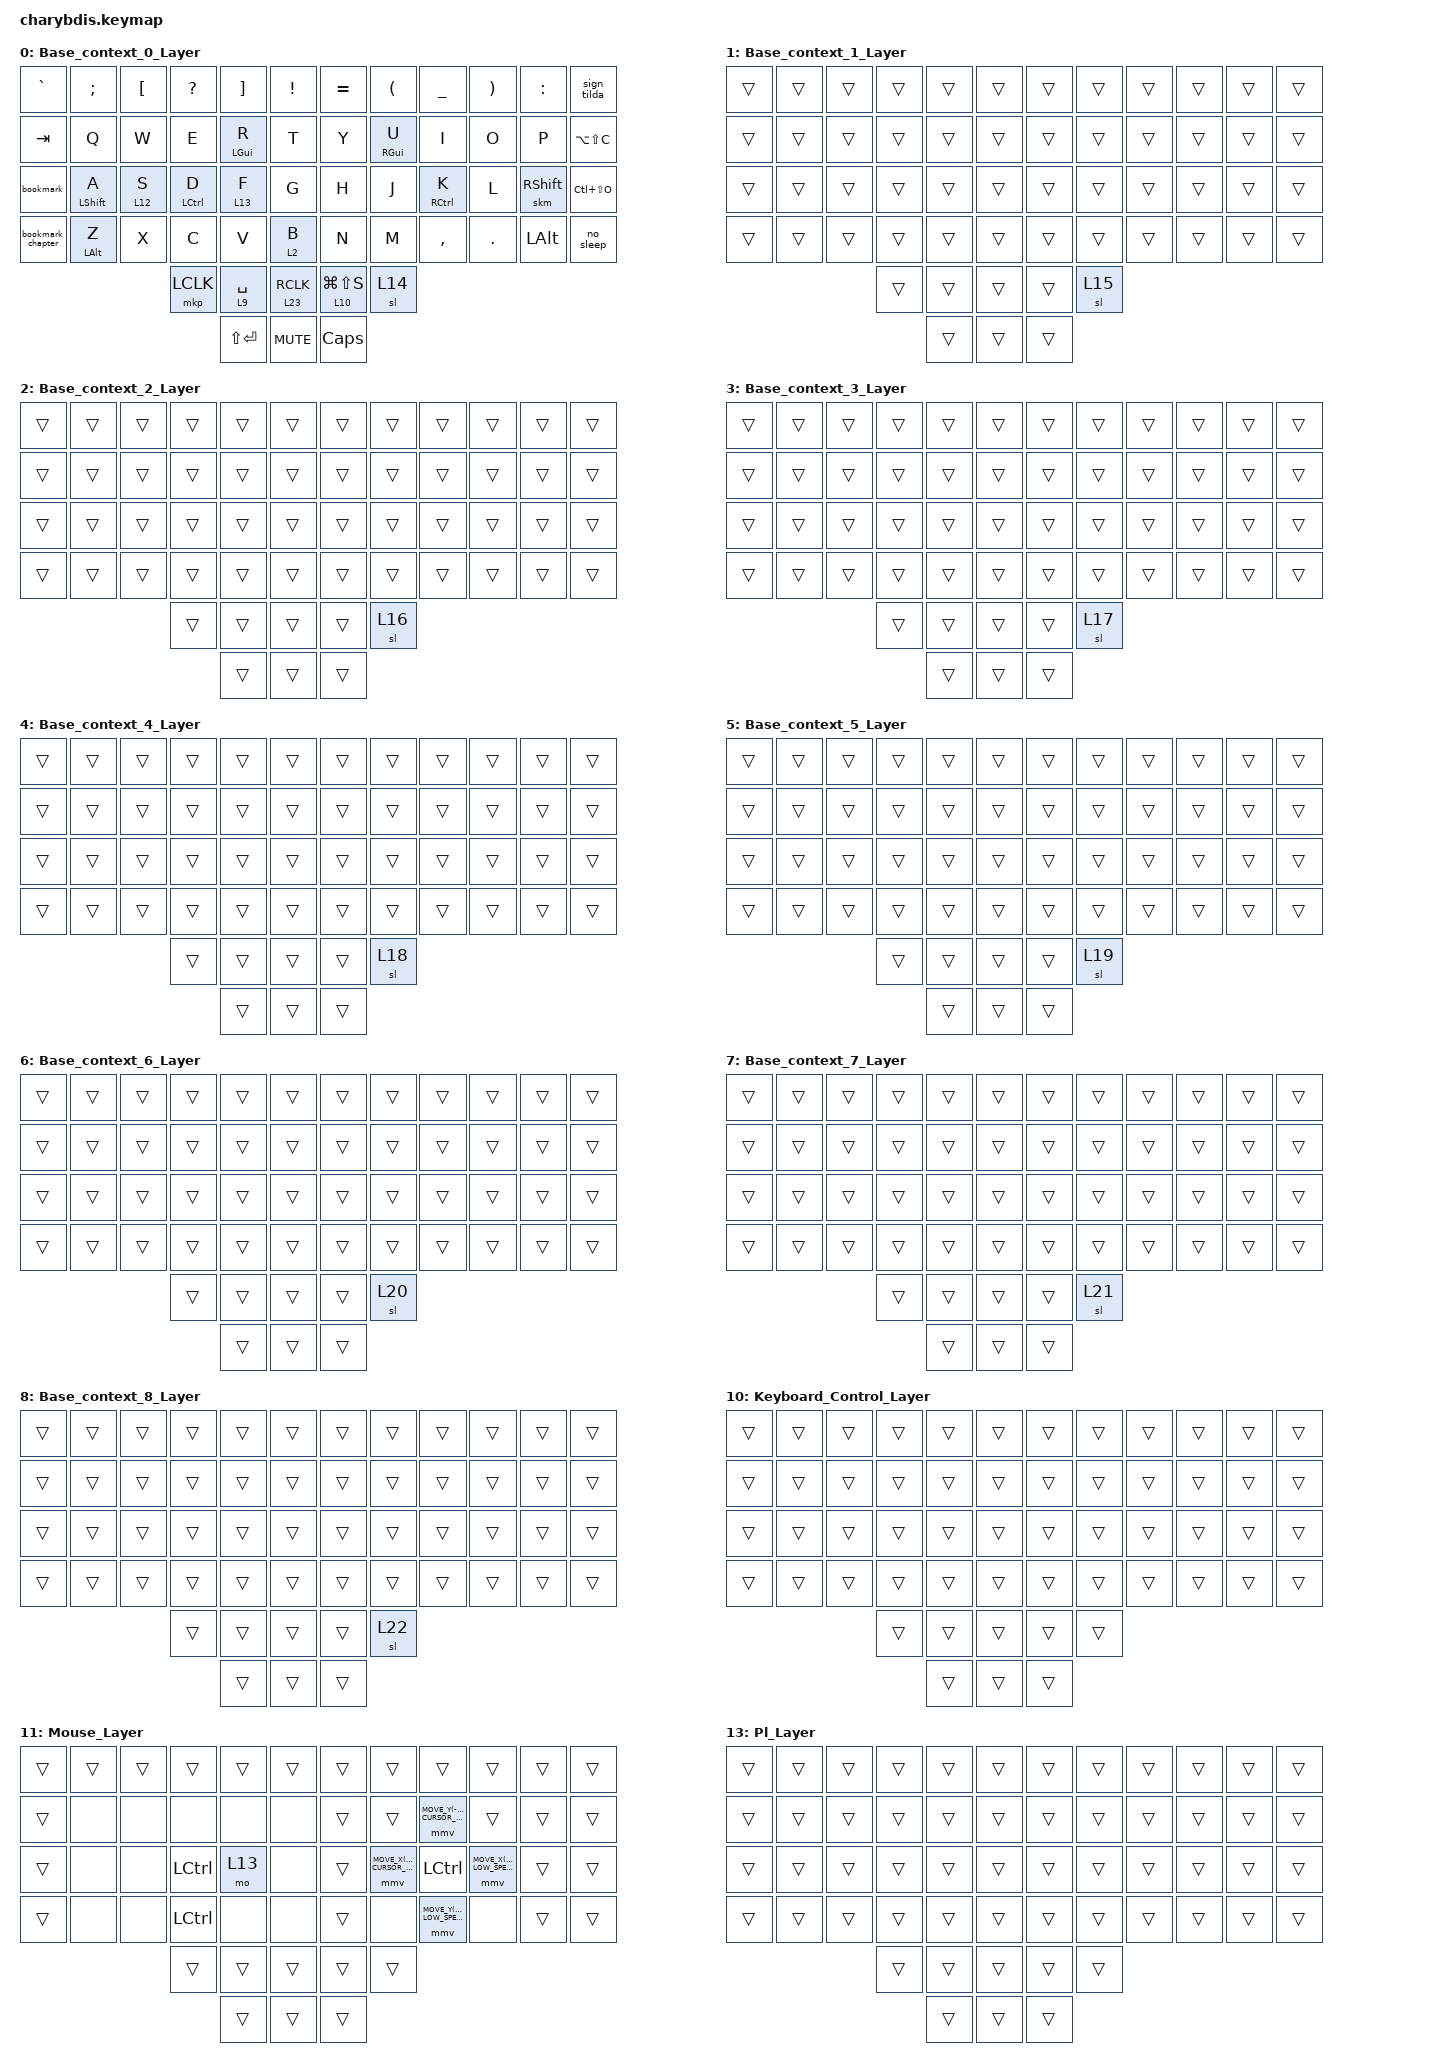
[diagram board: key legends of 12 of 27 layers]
#include <behaviors.dtsi>
#include <dt-bindings/zmk/keys.h>
#include <dt-bindings/zmk/pointing.h>

#define SIGN_COMBOS_LAYERS 0 1 2 3 4 5 6 7 8 9
#define SIGN_COMBOS_DELAY 40
#define SELECT_COMBOS_LAYERS 9
#define SELECT_COMBOS_DELAY 50
#define KEY_CURSOR_HIGH_SPEED 1200
#define KEY_CURSOR_LOW_SPEED  800

&lt {
    tapping-term-ms = <200>;
    flavor = "balanced";
    quick-tap-ms = <150>;
};

/ {
    behaviors {
        mmt: mmt {
            compatible = "zmk,behavior-hold-tap";
            #binding-cells = <2>;
            flavor = "balanced";
            tapping-term-ms = <200>;
            quick-tap-ms = <200>;
            global-quick-tap;
            bindings = <&kp>, <&kp>;
        };

        skl: skl {
            compatible = "zmk,behavior-sticky-key";
            label = "skl";
            #binding-cells = <1>;
            bindings = <&mo>;
            release-after-ms = <1000>;
            quick-release;
            ignore-modifiers;
        };

        skm: sticky_modif {
            compatible = "zmk,behavior-sticky-key";
            #binding-cells = <1>;
            bindings = <&kp>;
            release-after-ms = <1000>;
            quick-release;
        };

        // Define your custom delayed layer-tap behavior

        lt_delay: layer_tap_delay {
            compatible = "zmk,behavior-hold-tap";
            #binding-cells = <2>;
            flavor = "balanced";         // Enforces the time lag
            tapping-term-ms = <300>;           // Your time lag duration (e.g., 300ms)
            bindings = <&mo>, <&kp>;

            // Hold triggers momentary layer, tap triggers keypress
        };

        my_lt_rclk: my_lt_rclk {
            compatible = "zmk,behavior-hold-tap";
            #binding-cells = <2>;
            flavor = "tap-preferred"; // or "balanced" / "hold-preferred"
            tapping-term-ms = <200>;
            quick-tap-ms = <0>;
            bindings = <&mo>, <&mkp>;
        };
    };
};

/ {
    combos {
        compatible = "zmk,combos";

        sign_minus {
            timeout-ms = <SIGN_COMBOS_DELAY>;
            key-positions = <32 31>; // Triggers when positions 13 and 14 are pressed together
            bindings = <&kp MINUS>;    // Outputs the Escape key
            layers = <SIGN_COMBOS_LAYERS>;
        };

        sign_plus {
            timeout-ms = <SIGN_COMBOS_DELAY>;
            bindings = <&kp RS(PLUS)>;
            key-positions = <33 32>;
            layers = <SIGN_COMBOS_LAYERS>;
        };

        sign_asterix {
            timeout-ms = <SIGN_COMBOS_DELAY>;
            bindings = <&kp ASTERISK>;
            key-positions = <45 44>;
            layers = <SIGN_COMBOS_LAYERS>;
        };

        sign_divide {
            timeout-ms = <SIGN_COMBOS_DELAY>;
            bindings = <&kp SLASH>;
            key-positions = <44 43>;
            layers = <SIGN_COMBOS_LAYERS>;
        };

        sign_dollar {
            timeout-ms = <SIGN_COMBOS_DELAY>;
            bindings = <&kp DOLLAR>;
            key-positions = <20 19>;
            layers = <SIGN_COMBOS_LAYERS>;
        };

        sign_percent {
            timeout-ms = <SIGN_COMBOS_DELAY>;
            bindings = <&kp PERCENT>;
            key-positions = <21 20>;
            layers = <SIGN_COMBOS_LAYERS>;
        };

        sign_backslash {
            timeout-ms = <SIGN_COMBOS_DELAY>;
            bindings = <&kp BACKSLASH>;
            key-positions = <43 42>;
            layers = <SIGN_COMBOS_LAYERS>;
        };

        sign_at {
            timeout-ms = <SIGN_COMBOS_DELAY>;
            bindings = <&kp AT>;
            key-positions = <19 18>;
            layers = <SIGN_COMBOS_LAYERS>;
        };

        sign_caret {
            timeout-ms = <SIGN_COMBOS_DELAY>;
            bindings = <&kp CARET>;
            key-positions = <31 30>;
            layers = <SIGN_COMBOS_LAYERS>;
        };

        sign_double_quote {
            timeout-ms = <SIGN_COMBOS_DELAY>;
            bindings = <&kp DOUBLE_QUOTES>;
            key-positions = <21 19>;
            layers = <SIGN_COMBOS_LAYERS>;
        };

        sign_single_quote {
            bindings = <&kp SINGLE_QUOTE>;
            key-positions = <33 31>;
            layers = <SIGN_COMBOS_LAYERS>;
        };

        sign_pipe {
            timeout-ms = <SIGN_COMBOS_DELAY>;
            bindings = <&kp PIPE>;
            key-positions = <45 43>;
            layers = <SIGN_COMBOS_LAYERS>;
        };

        sign_hash {
            timeout-ms = <SIGN_COMBOS_DELAY>;
            bindings = <&kp HASH>;
            key-positions = <41 40>;
            layers = <SIGN_COMBOS_LAYERS>;
        };

        sign_amper {
            timeout-ms = <SIGN_COMBOS_DELAY>;
            bindings = <&kp AMPERSAND>;
            key-positions = <46 45>;
            layers = <SIGN_COMBOS_LAYERS>;
        };

        sign_l_brace {
            timeout-ms = <SIGN_COMBOS_DELAY>;
            bindings = <&kp LEFT_BRACE>;
            key-positions = <22 21>;
            layers = <SIGN_COMBOS_LAYERS>;
        };

        sign_r_brace {
            timeout-ms = <SIGN_COMBOS_DELAY>;
            bindings = <&kp RIGHT_BRACE>;
            key-positions = <34 33>;
            layers = <SIGN_COMBOS_LAYERS>;
        };

        sign_less {
            timeout-ms = <SIGN_COMBOS_DELAY>;
            bindings = <&kp LESS_THAN>;
            key-positions = <17 16>;
            layers = <SIGN_COMBOS_LAYERS>;
        };

        sign_greater {
            timeout-ms = <SIGN_COMBOS_DELAY>;
            bindings = <&kp GREATER_THAN>;
            key-positions = <29 28>;
            layers = <SIGN_COMBOS_LAYERS>;
        };

        mouse_scroll_down {
            timeout-ms = <SIGN_COMBOS_DELAY>;
            bindings = <&msc SCRL_DOWN>;
            key-positions = <40 38>;
            layers = <0 1 2 3 4 5 6 7 8 11>;
        };

        mouse_scroll_up {
            timeout-ms = <SIGN_COMBOS_DELAY>;
            bindings = <&msc SCRL_UP>;
            key-positions = <28 26>;
            layers = <0 1 2 3 4 5 6 7 8 11>;
        };

        mouse_left_click {
            timeout-ms = <SIGN_COMBOS_DELAY>;
            bindings = <&mkp MB1>;
            key-positions = <28 27>;
            layers = <0 1 2 3 4 5 6 7 8 11 12>;
        };

        mouse_right_click {
            timeout-ms = <SIGN_COMBOS_DELAY>;
            bindings = <&mkp MB2>;
            key-positions = <27 26>;
            layers = <0 1 2 3 4 5 6 7 8 11 12>;
        };

        mouse_back_click {
            timeout-ms = <SIGN_COMBOS_DELAY>;
            bindings = <&mkp MB4>;
            key-positions = <26 25>;
            layers = <0 1 2 3 4 5 6 7 8 11>;
        };

        mouse_forward_click {
            timeout-ms = <SIGN_COMBOS_DELAY>;
            bindings = <&mkp MB5>;
            key-positions = <38 37>;
            layers = <0 1 2 3 4 5 6 7 8 11>;
        };

        select_all {
            timeout-ms = <SELECT_COMBOS_DELAY>;
            bindings = <&kp LC(A)>;
            key-positions = <16 14>;
            layers = <SELECT_COMBOS_LAYERS>;
        };

        select_all_before {
            timeout-ms = <SELECT_COMBOS_DELAY>;
            bindings = <&kt RC(RS(HOME))>;
            key-positions = <15 14>;
            layers = <SELECT_COMBOS_LAYERS>;
        };

        select_all_after {
            timeout-ms = <SELECT_COMBOS_DELAY>;
            bindings = <&kp RC(RS(END))>;
            key-positions = <16 15>;
            layers = <SELECT_COMBOS_LAYERS>;
        };

        select_line_before {
            timeout-ms = <SELECT_COMBOS_DELAY>;
            bindings = <&kp RS(HOME)>;
            key-positions = <27 26>;
            layers = <SELECT_COMBOS_LAYERS>;
        };

        select_line_after {
            timeout-ms = <SELECT_COMBOS_DELAY>;
            bindings = <&kp RS(END)>;
            key-positions = <28 27>;
            layers = <SELECT_COMBOS_LAYERS>;
        };

        select_line_whole {
            timeout-ms = <SELECT_COMBOS_DELAY>;
            bindings = <&select_line>;
            key-positions = <28 26>;
            layers = <SELECT_COMBOS_LAYERS>;
        };

        select_world_whole {
            timeout-ms = <SELECT_COMBOS_DELAY>;
            bindings = <&select_word>;
            key-positions = <40 38>;
            layers = <SELECT_COMBOS_LAYERS>;
        };

        quick_layer_sl_1 {
            timeout-ms = <40>;
            bindings = <&sl 24>;
            key-positions = <40 39>;
            layers = <0 1 2 3 4 5 6 7 8>;
        };

        quick_layer_sl_2 {
            timeout-ms = <40>;
            bindings = <&sl 25>;
            key-positions = <39 38>;
            layers = <0 1 2 3 4 5 6 7 8>;
        };
    };
};

/ {
    macros {
        un: un {
            compatible = "zmk,behavior-macro";
            #binding-cells = <0>;
            bindings = <&kp U &kp N &kp N9 &kp N9 &kp L &kp T>;
            label = "UN";
        };

        ad: ad {
            compatible = "zmk,behavior-macro";
            #binding-cells = <0>;
            bindings = <&kp A &kp D &kp BSLH>;
            label = "AD";
        };

        email_w: email_w {
            compatible = "zmk,behavior-macro";
            #binding-cells = <0>;
            bindings = <&kp L &kp U &kp K &kp A &kp S &kp Z &kp DOT &kp M &kp U &kp S &kp Z &kp Y &kp N &kp S &kp K &kp I &kp AT &kp I &kp N &kp G &kp DOT &kp P &kp L>;
            label = "EMAIL_W";
        };

        passport: passport {
            compatible = "zmk,behavior-macro";
            #binding-cells = <0>;
            bindings = <&kp LS(E) &kp LS(R) &kp N6 &kp N7 &kp N8 &kp N4 &kp N8 &kp N1 &kp N9>;
            label = "PASSPORT";
        };

        id: id {
            compatible = "zmk,behavior-macro";
            #binding-cells = <0>;
            bindings = <&kp LS(D) &kp LS(E) &kp LS(R) &kp N6 &kp N1 &kp N1 &kp N2 &kp N4 &kp N2>;
            label = "ID";
        };

        email_h: email_h {
            compatible = "zmk,behavior-macro";
            #binding-cells = <0>;
            bindings = <&kp L &kp U &kp K &kp A &kp S &kp Z &kp M &kp U &kp S &kp Z &kp Y &kp N &kp S &kp K &kp I &kp N0 &kp AT &kp G &kp M &kp A &kp I &kp L &kp DOT &kp C &kp O &kp M>;
            label = "EMAIL_H";
        };

        email_h_spam: email_h_spam {
            compatible = "zmk,behavior-macro";
            #binding-cells = <0>;
            bindings = <&kp L &kp M &kp U &kp S &kp Z &kp Y &kp N &kp S &kp K &kp I &kp N1 &kp N9 &kp AT &kp G &kp M &kp A &kp I &kp L &kp DOT &kp C &kp O &kp M>;
            label = "EMAIL_H_SPAM";
        };

        select_line: select_line {
            compatible = "zmk,behavior-macro";
            #binding-cells = <0>;
            wait-ms = <5>;
            tap-ms = <5>;
            bindings =
                <&macro_tap>,
                <&kp HOME>,
                <&macro_press>,
                <&kp LSHFT>,
                <&macro_tap>,
                <&kp END>,
                <&macro_release>,
                <&kp LSHFT>;
        };

        select_word: select_word {
            compatible = "zmk,behavior-macro";
            #binding-cells = <0>;
            wait-ms = <5>;
            tap-ms = <5>;
            bindings =
                <&macro_press>,
                <&kp LCTRL>,
                <&macro_tap>,
                <&kp RIGHT>,
                <&macro_release>,
                <&kp LCTRL>,
                <&macro_press>,
                <&kp LCTRL>,
                <&macro_press>,
                <&kp LSHIFT>,
                <&macro_tap>,
                <&kp LEFT>,
                <&macro_release>,
                <&kp LSHIFT>,
                <&macro_release>,
                <&kp LCTRL>;
        };

        linux_ls: linux_ls {
            compatible = "zmk,behavior-macro";
            #binding-cells = <0>;
            bindings = <&kp L &kp S &kp SPACE &kp MINUS &kp MINUS &kp A &kp L &kp L &kp SPACE &kp MINUS &kp L &kp H &kp S>;
            label = "LINUX_LS";
        };

        linux_hdfs_ls: linux_hdfs_ls {
            compatible = "zmk,behavior-macro";
            #binding-cells = <0>;
            bindings = <&kp H &kp D &kp F &kp S &kp SPACE &kp D &kp F &kp S &kp SPACE &kp MINUS &kp L &kp S &kp SPACE &kp MINUS &kp H>;
            label = "LINUX_HDFS_LS";
        };

        linux_git_track: linux_git_origin {
            compatible = "zmk,behavior-macro";
            #binding-cells = <0>;
            bindings = <&kp G &kp I &kp T &kp SPACE &kp C &kp H &kp E &kp C &kp K &kp O &kp U &kp T &kp SPACE &kp MINUS &kp MINUS &kp T &kp R &kp A &kp C &kp K &kp SPACE &kp O &kp R &kp I &kp G &kp I &kp N &kp FSLH>;
            label = "LINUX_GIT_ORIGIN";
        };

        linux_git_commit: linux_git_commit {
            compatible = "zmk,behavior-macro";
            #binding-cells = <0>;
            bindings = <&kp G &kp I &kp T &kp SPACE &kp C &kp O &kp M &kp M &kp I &kp T &kp SPACE &kp MINUS &kp M &kp SQT &kp DOT &kp SQT>;
            label = "LINUX_GIT_COMMIT";
        };

        path_w_sand: path_w_project {
            compatible = "zmk,behavior-macro";
            #binding-cells = <0>;
            bindings = <&kp FSLH &kp S &kp A &kp N &kp D &kp B &kp O &kp X &kp FSLH &kp C &kp O &kp O &kp UNDER &kp A &kp N &kp A &kp L &kp Y &kp S &kp I &kp S &kp UNDER &kp C &kp H &kp A &kp P &kp T &kp E &kp R &kp FSLH &kp F &kp I &kp L>;
            label = "PATH_W_PROJECT";
        };

        linux_nvidia: linux_nvidia {
            compatible = "zmk,behavior-macro";
            #binding-cells = <0>;
            bindings = <&kp N &kp V &kp I &kp D &kp I &kp A &kp MINUS &kp S &kp M &kp I &kp SPACE &kp MINUS &kp L &kp SPACE &kp N1>;
            label = "LINUX_NVIDIA";
        };

        jupyter_new_cell_above: jupyter_new_cell_above {
            compatible = "zmk,behavior-macro";
            #binding-cells = <0>;
            bindings = <&kp ESC &kp A &kp ENTER>;
            label = "JUPYTER_NEW_CALL_ABOVE";
        };

        jupyter_new_cell_below: jupyter_new_cell_below {
            compatible = "zmk,behavior-macro";
            #binding-cells = <0>;
            bindings = <&kp ESC &kp B &kp ENTER>;
            label = "JUPYTER_CELL_CELL_BELOW";
        };

        jupyter_restart: jupyter_restart {
            compatible = "zmk,behavior-macro";
            #binding-cells = <0>;
            bindings = <&kp ESCAPE &kp N0 &kp N0>;
            label = "JUPYTER_RESTART";
        };

        jupyter_cell_up: jupyter_cell_up {
            compatible = "zmk,behavior-macro";
            #binding-cells = <0>;
            bindings = <&kp ESC &kp UP_ARROW &kp ENTER>;
            label = "JUPYTER_CELL_UP";
        };

        jupyter_cell_down: jupyter_cell_down {
            compatible = "zmk,behavior-macro";
            #binding-cells = <0>;
            bindings = <&kp ESC &kp DOWN_ARROW &kp ENTER>;
            label = "JUPYTER_CELL_DOWN";
        };

        jupyter_cell_delete: jupyter_cell_delete {
            compatible = "zmk,behavior-macro";
            #binding-cells = <0>;
            bindings = <&kp ESCAPE &kp D &kp D>;
            label = "JUPYTER_CELL_DELETE";
        };

        jupyter_cell_markdown: jupyter_cell_markdown {
            compatible = "zmk,behavior-macro";
            #binding-cells = <0>;
            bindings = <&kp ESC &kp M>;
            label = "JUPYTER_CELL_MARKDOWN";
        };

        no_sleep: no_sleep {
            compatible = "zmk,behavior-macro";
            #binding-cells = <0>;
            bindings =
                <&kp LEFT_ALT>,
                <&macro_wait_time 50>,
                <&kp Y>,
                <&macro_wait_time 50>,
                <&kp B>;

            label = "NO_SLEEP";
        };

        sign_tilda: sign_tilda {
            compatible = "zmk,behavior-macro";
            #binding-cells = <0>;
            bindings = <&kp TILDE &kp TILDE &kp BACKSPACE>;
            label = "SIGN_TILDA";
        };

        path_lap_projects: path_lap_projects {
            compatible = "zmk,behavior-macro";
            #binding-cells = <0>;
            bindings = <&kp LS(C) &kp COLON &kp BSLH &kp LS(U) &kp S &kp E &kp R &kp S &kp BSLH &kp LS(U) &kp LS(N) &kp N9 &kp N9 &kp LS(L) &kp LS(T) &kp BSLH &kp LS(P) &kp R &kp O &kp J &kp E &kp C &kp T &kp S>;
            label = "PATH_LAP_PROJECTS";
        };

        zip_c: zip_c {
            compatible = "zmk,behavior-macro";
            #binding-cells = <0>;
            bindings = <&kp N4 &kp N0 &kp N0 &kp N8 &kp N4>;
            label = "ZIP_C";
        };

        bookmark: bookmark {
            compatible = "zmk,behavior-macro";
            #binding-cells = <0>;
            bindings = <&kp POUND &kp A &kp UNDER &kp N1 &kp UNDER>;
            label = "BOOKMARK";
        };

        bookmark_chapter: bookmark_chapter {
            compatible = "zmk,behavior-macro";
            #binding-cells = <0>;
            bindings = <&kp PIPE &kp C &kp DOT>;
            label = "BOOKMARK_CHAPTER";
        };

        citrix_leave: citrix_leave {
            compatible = "zmk,behavior-macro";
            #binding-cells = <0>;
            bindings = <&kp LC(LA(PAUSE_BREAK)) &kp DOWN_ARROW &kp ENTER>;
            label = "CITRIX_LEAVE";
        };

        czesc: czesc {
            compatible = "zmk,behavior-macro";
            #binding-cells = <0>;
            bindings = <&kp LS(C) &kp Z &kp E &kp RA(S) &kp RA(C) &kp COMMA &kp SPACE>;
            label = "CZESC";
        };

        smile: smile {
            compatible = "zmk,behavior-macro";
            #binding-cells = <0>;
            bindings = <&kp COLON &kp LS(D)>;
            label = "SMILE";
        };

        sign_less_eq: sign_less_eq {
            compatible = "zmk,behavior-macro";
            #binding-cells = <0>;
            bindings = <&kp SPACE &kp LT &kp EQUAL &kp SPACE>;
            label = "SIGN_LESS_EQ";
        };

        sign_great_eq: sign_great_eq {
            compatible = "zmk,behavior-macro";
            #binding-cells = <0>;
            bindings = <&kp SPACE &kp GT &kp EQUAL &kp SPACE>;
            label = "SIGN_GREAT_EQ";
        };

        sign_diff: sign_diff {
            compatible = "zmk,behavior-macro";
            #binding-cells = <0>;
            bindings = <&kp SPACE &kp EXCL &kp EQUAL &kp SPACE>;
            label = "SIGN_DIFF";
        };

        sign_eq: sign_eq {
            compatible = "zmk,behavior-macro";
            #binding-cells = <0>;
            bindings = <&kp SPACE &kp EQUAL &kp SPACE>;
            label = "SIGN_EQ";
        };
    };

    keymap {
        compatible = "zmk,keymap";

        Base_context_0_Layer {
            bindings = <
&kp GRAVE          &kp SEMI          &kp LEFT_BRACKET  &kp QUESTION         &kp RIGHT_BRACKET  &kp EXCL                  &kp EQUAL           &kp LEFT_PARENTHESIS  &kp UNDER             &kp RIGHT_PARENTHESIS  &kp COLON         &sign_tilda
&kp TAB            &kp Q             &kp W             &kp E                &mmt LEFT_GUI R    &kp T                     &kp Y               &mmt RIGHT_GUI U      &kp I                 &kp O                  &kp P             &kp LA(LS(C))
&bookmark          &mmt LEFT_SHIFT A &lt_delay 12 S    &mmt LEFT_CONTROL D  &lt_delay 13 F     &kp G                     &kp H               &kp J                 &mmt RIGHT_CONTROL K  &kp L                  &skm RIGHT_SHIFT  &kp LC(LS(O))
&bookmark_chapter  &mmt LEFT_ALT Z   &kp X             &kp C                &kp V              &lt 2 B                   &kp N               &kp M                 &kp COMMA             &kp DOT                &kp LEFT_ALT      &no_sleep
                                                       &mkp LCLK            &lt 9 SPACE        &my_lt_rclk 23 RCLK       &lt 10 LG(LS(S))    &sl 14
                                                                            &kp LS(ENTER)      &kp C_MUTE                &kp CAPSLOCK
            >;
        };

        Base_context_1_Layer {
            bindings = <
&trans  &trans  &trans  &trans  &trans  &trans    &trans  &trans  &trans  &trans  &trans  &trans
&trans  &trans  &trans  &trans  &trans  &trans    &trans  &trans  &trans  &trans  &trans  &trans
&trans  &trans  &trans  &trans  &trans  &trans    &trans  &trans  &trans  &trans  &trans  &trans
&trans  &trans  &trans  &trans  &trans  &trans    &trans  &trans  &trans  &trans  &trans  &trans
                        &trans  &trans  &trans    &trans  &sl 15
                                &trans  &trans    &trans
            >;
        };

        Base_context_2_Layer {
            bindings = <
&trans  &trans  &trans  &trans  &trans  &trans    &trans  &trans  &trans  &trans  &trans  &trans
&trans  &trans  &trans  &trans  &trans  &trans    &trans  &trans  &trans  &trans  &trans  &trans
&trans  &trans  &trans  &trans  &trans  &trans    &trans  &trans  &trans  &trans  &trans  &trans
&trans  &trans  &trans  &trans  &trans  &trans    &trans  &trans  &trans  &trans  &trans  &trans
                        &trans  &trans  &trans    &trans  &sl 16
                                &trans  &trans    &trans
            >;
        };

        Base_context_3_Layer {
            bindings = <
&trans  &trans  &trans  &trans  &trans  &trans    &trans  &trans  &trans  &trans  &trans  &trans
&trans  &trans  &trans  &trans  &trans  &trans    &trans  &trans  &trans  &trans  &trans  &trans
&trans  &trans  &trans  &trans  &trans  &trans    &trans  &trans  &trans  &trans  &trans  &trans
&trans  &trans  &trans  &trans  &trans  &trans    &trans  &trans  &trans  &trans  &trans  &trans
                        &trans  &trans  &trans    &trans  &sl 17
                                &trans  &trans    &trans
            >;
        };

        Base_context_4_Layer {
            bindings = <
&trans  &trans  &trans  &trans  &trans  &trans    &trans  &trans  &trans  &trans  &trans  &trans
&trans  &trans  &trans  &trans  &trans  &trans    &trans  &trans  &trans  &trans  &trans  &trans
&trans  &trans  &trans  &trans  &trans  &trans    &trans  &trans  &trans  &trans  &trans  &trans
&trans  &trans  &trans  &trans  &trans  &trans    &trans  &trans  &trans  &trans  &trans  &trans
                        &trans  &trans  &trans    &trans  &sl 18
                                &trans  &trans    &trans
            >;
        };

        Base_context_5_Layer {
            bindings = <
&trans  &trans  &trans  &trans  &trans  &trans    &trans  &trans  &trans  &trans  &trans  &trans
&trans  &trans  &trans  &trans  &trans  &trans    &trans  &trans  &trans  &trans  &trans  &trans
&trans  &trans  &trans  &trans  &trans  &trans    &trans  &trans  &trans  &trans  &trans  &trans
&trans  &trans  &trans  &trans  &trans  &trans    &trans  &trans  &trans  &trans  &trans  &trans
                        &trans  &trans  &trans    &trans  &sl 19
                                &trans  &trans    &trans
            >;
        };

        Base_context_6_Layer {
            bindings = <
&trans  &trans  &trans  &trans  &trans  &trans    &trans  &trans  &trans  &trans  &trans  &trans
&trans  &trans  &trans  &trans  &trans  &trans    &trans  &trans  &trans  &trans  &trans  &trans
&trans  &trans  &trans  &trans  &trans  &trans    &trans  &trans  &trans  &trans  &trans  &trans
&trans  &trans  &trans  &trans  &trans  &trans    &trans  &trans  &trans  &trans  &trans  &trans
                        &trans  &trans  &trans    &trans  &sl 20
                                &trans  &trans    &trans
            >;
        };

        Base_context_7_Layer {
            bindings = <
&trans  &trans  &trans  &trans  &trans  &trans    &trans  &trans  &trans  &trans  &trans  &trans
&trans  &trans  &trans  &trans  &trans  &trans    &trans  &trans  &trans  &trans  &trans  &trans
&trans  &trans  &trans  &trans  &trans  &trans    &trans  &trans  &trans  &trans  &trans  &trans
&trans  &trans  &trans  &trans  &trans  &trans    &trans  &trans  &trans  &trans  &trans  &trans
                        &trans  &trans  &trans    &trans  &sl 21
                                &trans  &trans    &trans
            >;
        };

        Base_context_8_Layer {
            bindings = <
&trans  &trans  &trans  &trans  &trans  &trans    &trans  &trans  &trans  &trans  &trans  &trans
&trans  &trans  &trans  &trans  &trans  &trans    &trans  &trans  &trans  &trans  &trans  &trans
&trans  &trans  &trans  &trans  &trans  &trans    &trans  &trans  &trans  &trans  &trans  &trans
&trans  &trans  &trans  &trans  &trans  &trans    &trans  &trans  &trans  &trans  &trans  &trans
                        &trans  &trans  &trans    &trans  &sl 22
                                &trans  &trans    &trans
            >;
        };

        Navig_Layer {
            bindings = <
&mt GRAVE F12  &mt SEMI F1               &mt LEFT_BRACKET F2  &mt QUESTION F3       &mt RIGHT_BRACKET F4  &mt EXCL F5             &mt EQUAL F6       &mt LEFT_PARENTHESIS F6  &mt UNDER F8                 &mt RIGHT_PARENTHESIS F9  &mt COLON F10             &mt TILDE F11
&trans         &kp ESC                   &kp HOME             &kp UP_ARROW          &mt LEFT_GUI END      &mt (C_VOL_UP) LC(X)    &kp PAGE_UP        &mt RIGHT_GUI NUMBER_7   &kp NUMBER_8                 &kp NUMBER_9              &kp RC(RA(TAB))           &trans
&trans         &mt LEFT_SHIFT ENTER      &kp LEFT_ARROW       &mt LEFT_CONTROL TAB  &kp RIGHT_ARROW       &mt (C_VOL_DN) LC(C)    &kp PAGE_DOWN      &kp NUMBER_4             &mmt RIGHT_CONTROL NUMBER_5  &kp NUMBER_6              &mmt (RIGHT_SHIFT) LG(T)  &trans
&trans         &mt (LEFT_ALT) RC(SLASH)  &kp BACKSPACE        &kp DOWN_ARROW        &kp DELETE            &kp LC(V)               &kp K_APPLICATION  &kp NUMBER_1             &mt COMMA NUMBER_2           &mt DOT NUMBER_3          &kp LEFT_ALT              &trans
                                                        &trans                &trans                &trans                  &citrix_leave      &kp NUMBER_0
                                                                              &trans                &trans                  &kp RC(E)
            >;
        };

        Keyboard_Control_Layer {
            bindings = <
&trans  &trans  &trans  &trans  &trans  &trans    &trans  &trans  &trans  &trans  &trans  &trans
&trans  &trans  &trans  &trans  &trans  &trans    &trans  &trans  &trans  &trans  &trans  &trans
&trans  &trans  &trans  &trans  &trans  &trans    &trans  &trans  &trans  &trans  &trans  &trans
&trans  &trans  &trans  &trans  &trans  &trans    &trans  &trans  &trans  &trans  &trans  &trans
                        &trans  &trans  &trans    &trans  &trans
                                &trans  &trans    &trans
            >;
        };

        Mouse_Layer {
            bindings = <
&trans  &trans  &trans  &trans            &trans  &trans    &trans  &trans                              &trans                              &trans                             &trans  &trans
&trans  &none   &none   &none             &none   &none     &trans  &trans                              &mmv MOVE_Y(-KEY_CURSOR_LOW_SPEED)  &trans                             &trans  &trans
&trans  &none   &none   &kp LEFT_CONTROL  &mo 13  &none     &trans  &mmv MOVE_X(-KEY_CURSOR_LOW_SPEED)  &kp LEFT_CONTROL                    &mmv MOVE_X(KEY_CURSOR_LOW_SPEED)  &trans  &trans
&trans  &none   &none   &kp LEFT_CONTROL  &none   &none     &trans  &none                               &mmv MOVE_Y(KEY_CURSOR_LOW_SPEED)   &none                              &trans  &trans
                        &trans            &trans  &trans    &trans  &trans
                                          &trans  &trans    &trans
            >;
        };

        Capital_Layer {
            bindings = <
&trans  &kp LS(N1)  &kp LS(N2)  &kp LS(N3)          &kp LS(N4)  &kp LS(N5)    &kp LS(N6)      &kp LS(N7)  &kp LS(N8)     &kp LS(N9)   &kp LS(N0)  &trans
&trans  &kp LS(Q)   &kp LS(W)   &kp LS(E)           &kp LS(R)   &kp LS(T)     &kp LS(Y)       &kp LS(U)   &kp LS(I)      &kp LS(O)    &kp LS(P)   &trans
&trans  &kp LS(A)   &kp LS(S)   &mmt (LCTRL) LS(D)  &kp LS(F)   &kp LS(G)     &kp LS(H)       &kp LS(J)   &kp LS(K)      &kp LS(L)    &trans      &trans
&trans  &kp LS(Z)   &kp LS(X)   &kp LS(C)           &kp LS(V)   &kp LS(B)     &kp LS(N)       &kp LS(M)   &kp LS(COMMA)  &kp LS(DOT)  &trans      &trans
                                &mkp LCLK           &czesc      &trans        &sign_less_eq   &sign_eq
                                                    &smile      &trans        &sign_great_eq
            >;
        };

        Pl_Layer {
            bindings = <
&trans  &trans  &trans  &trans  &trans  &trans    &trans  &trans  &trans  &trans  &trans  &trans
&trans  &trans  &trans  &trans  &trans  &trans    &trans  &trans  &trans  &trans  &trans  &trans
&trans  &trans  &trans  &trans  &trans  &trans    &trans  &trans  &trans  &trans  &trans  &trans
&trans  &trans  &trans  &trans  &trans  &trans    &trans  &trans  &trans  &trans  &trans  &trans
                        &trans  &trans  &trans    &trans  &trans
                                &trans  &trans    &trans
            >;
        };

        Context_0_Layer {
            bindings = <
&trans  &to 0      &to 1      &to 2               &to 3   &to 4     &to 5                   &to 6                     &to 7               &to 8                      &none             &trans
&trans  &kp RA(L)  &kp RA(O)  &kp RA(E)           &trans  &trans    &jupyter_cell_delete    &trans                    &jupyter_cell_up    &trans                     &trans            &trans
&trans  &kp RA(A)  &kp RA(S)  &mmt (LCTRL) RA(N)  &trans  &trans    &none                   &kp RC(LS(LEFT_BRACKET))  &kp LC(ENTER)       &kp RC(RS(RIGHT_BRACKET))  &kp LS(ENTER)     &trans
&trans  &kp RA(Z)  &kp RA(X)  &kp RA(C)           &trans  &trans    &jupyter_cell_markdown  &jupyter_new_cell_above   &jupyter_cell_down  &jupyter_new_cell_below    &jupyter_restart  &trans
                              &trans              &trans  &trans    &trans                  &trans
                                                  &trans  &trans    &trans
            >;
        };

        Context_1_Layer {
            bindings = <
&trans  &to 0      &to 1      &to 2               &to 3   &to 4     &to 5   &to 6   &to 7   &to 8   &none   &trans
&trans  &kp RA(L)  &kp RA(O)  &kp RA(E)           &trans  &trans    &trans  &trans  &trans  &trans  &trans  &trans
&trans  &kp RA(A)  &kp RA(S)  &mmt (LCTRL) RA(N)  &trans  &trans    &trans  &trans  &trans  &trans  &trans  &trans
&trans  &kp RA(Z)  &kp RA(X)  &kp RA(C)           &trans  &trans    &trans  &trans  &trans  &trans  &trans  &trans
                              &trans              &trans  &trans    &trans  &trans
                                                  &trans  &trans    &trans
            >;
        };

        Context_2_Layer {
            bindings = <
&trans  &to 0      &to 1      &to 2               &to 3   &to 4     &to 5   &to 6   &to 7   &to 8   &none   &trans
&trans  &kp RA(L)  &kp RA(O)  &kp RA(E)           &trans  &trans    &trans  &trans  &trans  &trans  &trans  &trans
&trans  &kp RA(A)  &kp RA(S)  &mmt (LCTRL) RA(N)  &trans  &trans    &trans  &trans  &trans  &trans  &trans  &trans
&trans  &kp RA(Z)  &kp RA(X)  &kp RA(C)           &trans  &trans    &trans  &trans  &trans  &trans  &trans  &trans
                              &trans              &trans  &trans    &trans  &trans
                                                  &trans  &trans    &trans
            >;
        };

        Context_3_Layer {
            bindings = <
&trans  &to 0      &to 1      &to 2               &to 3   &to 4     &to 5   &to 6   &to 7   &to 8   &none   &trans
&trans  &kp RA(L)  &kp RA(O)  &kp RA(E)           &trans  &trans    &trans  &trans  &trans  &trans  &trans  &trans
&trans  &kp RA(A)  &kp RA(S)  &mmt (LCTRL) RA(N)  &trans  &trans    &trans  &trans  &trans  &trans  &trans  &trans
&trans  &kp RA(Z)  &kp RA(X)  &kp RA(C)           &trans  &trans    &trans  &trans  &trans  &trans  &trans  &trans
                              &trans              &trans  &trans    &trans  &trans
                                                  &trans  &trans    &trans
            >;
        };

        Context_4_Layer {
            bindings = <
&trans  &to 0      &to 1      &to 2               &to 3   &to 4     &to 5   &to 6   &to 7   &to 8   &none   &trans
&trans  &kp RA(L)  &kp RA(O)  &kp RA(E)           &trans  &trans    &trans  &trans  &trans  &trans  &trans  &trans
&trans  &kp RA(A)  &kp RA(S)  &mmt (LCTRL) RA(N)  &trans  &trans    &trans  &trans  &trans  &trans  &trans  &trans
&trans  &kp RA(Z)  &kp RA(X)  &kp RA(C)           &trans  &trans    &trans  &trans  &trans  &trans  &trans  &trans
                              &trans              &trans  &trans    &trans  &trans
                                                  &trans  &trans    &trans
            >;
        };

        Context_5_Layer {
            bindings = <
&trans  &to 0      &to 1      &to 2               &to 3   &to 4     &to 5   &to 6   &to 7   &to 8   &none   &trans
&trans  &kp RA(L)  &kp RA(O)  &kp RA(E)           &trans  &trans    &trans  &trans  &trans  &trans  &trans  &trans
&trans  &kp RA(A)  &kp RA(S)  &mmt (LCTRL) RA(N)  &trans  &trans    &trans  &trans  &trans  &trans  &trans  &trans
&trans  &kp RA(Z)  &kp RA(X)  &kp RA(C)           &trans  &trans    &trans  &trans  &trans  &trans  &trans  &trans
                              &trans              &trans  &trans    &trans  &trans
                                                  &trans  &trans    &trans
            >;
        };

        Context_6_Layer {
            bindings = <
&trans  &to 0      &to 1      &to 2               &to 3   &to 4     &to 5   &to 6   &to 7   &to 8   &none   &trans
&trans  &kp RA(L)  &kp RA(O)  &kp RA(E)           &trans  &trans    &trans  &trans  &trans  &trans  &trans  &trans
&trans  &kp RA(A)  &kp RA(S)  &mmt (LCTRL) RA(N)  &trans  &trans    &trans  &trans  &trans  &trans  &trans  &trans
&trans  &kp RA(Z)  &kp RA(X)  &kp RA(C)           &trans  &trans    &trans  &trans  &trans  &trans  &trans  &trans
                              &trans              &trans  &trans    &trans  &trans
                                                  &trans  &trans    &trans
            >;
        };

        Context_7_Layer {
            bindings = <
&trans  &to 0      &to 1      &to 2               &to 3   &to 4     &to 5   &to 6   &to 7   &to 8   &none   &trans
&trans  &kp RA(L)  &kp RA(O)  &kp RA(E)           &trans  &trans    &trans  &trans  &trans  &trans  &trans  &trans
&trans  &kp RA(A)  &kp RA(S)  &mmt (LCTRL) RA(N)  &trans  &trans    &trans  &trans  &trans  &trans  &trans  &trans
&trans  &kp RA(Z)  &kp RA(X)  &kp RA(C)           &trans  &trans    &trans  &trans  &trans  &trans  &trans  &trans
                              &trans              &trans  &trans    &trans  &trans
                                                  &trans  &trans    &trans
            >;
        };

        Context_8_Layer {
            bindings = <
&trans  &to 0      &to 1      &to 2               &to 3   &to 4     &to 5   &to 6   &to 7   &to 8   &none   &trans
&trans  &kp RA(L)  &kp RA(O)  &kp RA(E)           &trans  &trans    &trans  &trans  &trans  &trans  &trans  &trans
&trans  &kp RA(A)  &kp RA(S)  &mmt (LCTRL) RA(N)  &trans  &trans    &trans  &trans  &trans  &trans  &trans  &trans
&trans  &kp RA(Z)  &kp RA(X)  &kp RA(C)           &trans  &trans    &trans  &trans  &trans  &trans  &trans  &trans
                              &trans              &trans  &trans    &trans  &trans
                                                  &trans  &trans    &trans
            >;
        };

        Quick_Layer_0 {
            bindings = <
&trans  &trans  &trans     &trans    &trans         &trans      &trans  &path_w_sand        &trans  &trans  &trans  &trans
&trans  &zip_c  &trans     &trans    &trans         &trans      &trans  &path_lap_projects  &trans  &trans  &trans  &trans
&trans  &ad     &un        &kp TAB   &trans         &trans      &trans  &trans              &trans  &trans  &trans  &trans
&trans  &id     &passport  &email_h  &email_h_spam  &email_w    &trans  &trans              &trans  &trans  &trans  &trans
                           &trans    &trans         &trans      &trans  &trans
                                     &trans         &trans      &trans
            >;
        };

        Quick_Layer_1 {
            bindings = <
&trans  &trans  &trans  &trans             &trans  &trans              &trans          &trans  &trans  &trans     &trans  &trans
&trans  &trans  &trans  &trans             &trans  &trans              &trans          &trans  &trans  &trans     &trans  &trans
&trans  &trans  &trans  &trans             &trans  &linux_git_track    &linux_hdfs_ls  &trans  &trans  &linux_ls  &trans  &trans
&trans  &trans  &trans  &linux_git_commit  &trans  &trans              &linux_nvidia   &trans  &trans  &trans     &trans  &trans
                        &trans             &trans  &trans              &trans          &trans
                                           &trans  &trans              &trans
            >;
        };

        Quick_Layer_2 {
            bindings = <
&trans  &trans  &trans  &trans  &trans  &trans    &trans  &trans  &trans  &trans  &trans  &trans
&trans  &trans  &trans  &trans  &trans  &trans    &trans  &trans  &trans  &trans  &trans  &trans
&trans  &trans  &trans  &trans  &trans  &trans    &trans  &trans  &trans  &trans  &trans  &trans
&trans  &trans  &trans  &trans  &trans  &trans    &trans  &trans  &trans  &trans  &trans  &trans
                        &trans  &trans  &trans    &trans  &trans
                                &trans  &trans    &trans
            >;
        };

        Quick_Layer_3 {
            bindings = <
&trans  &trans  &trans  &trans  &trans  &trans    &trans  &trans  &trans  &trans  &trans  &trans
&trans  &trans  &trans  &trans  &trans  &trans    &trans  &trans  &trans  &trans  &trans  &trans
&trans  &trans  &trans  &trans  &trans  &trans    &trans  &trans  &trans  &trans  &trans  &trans
&trans  &trans  &trans  &trans  &trans  &trans    &trans  &trans  &trans  &trans  &trans  &trans
                        &trans  &trans  &trans    &trans  &trans
                                &trans  &trans    &trans
            >;
        };
    };
};
